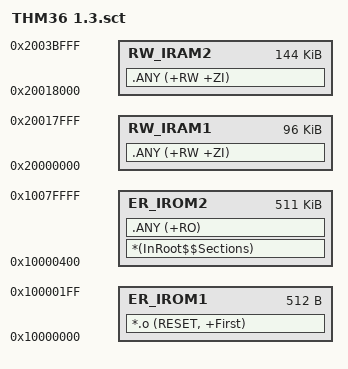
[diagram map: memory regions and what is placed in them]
; *************************************************************
; *** Scatter-Loading Description File generated by uVision ***
; *************************************************************

LR_IROM1 0x10000000 0x00000200  {    ; load region size_region
  ER_IROM1 0x10000000 0x00000200  {  ; load address = execution address
   *.o (RESET, +First)
  }
}

LR_IROM2 0x10000400 0x0007FC00 {    ; load region size_region
ER_IROM2 0x10000400 0x0007FC00  {  ; load address = execution address
   *(InRoot$$Sections)
   .ANY (+RO)
  }
   RW_IRAM1 0x20000000 0x0018000  {  ; RW data
   .ANY (+RW +ZI)
  }
 RW_IRAM2 0x20018000 0x00024000  {  ; RW data
   .ANY (+RW +ZI)
  }
}

;LR_IROM3 0x10080000 0x08000000  {
;ER_IROM3 0x10080000 0x08000000  {  ; load address = execution address
   ;spi_controller_w25q256.o   (i.XIP_Test)
  ;}
;}

